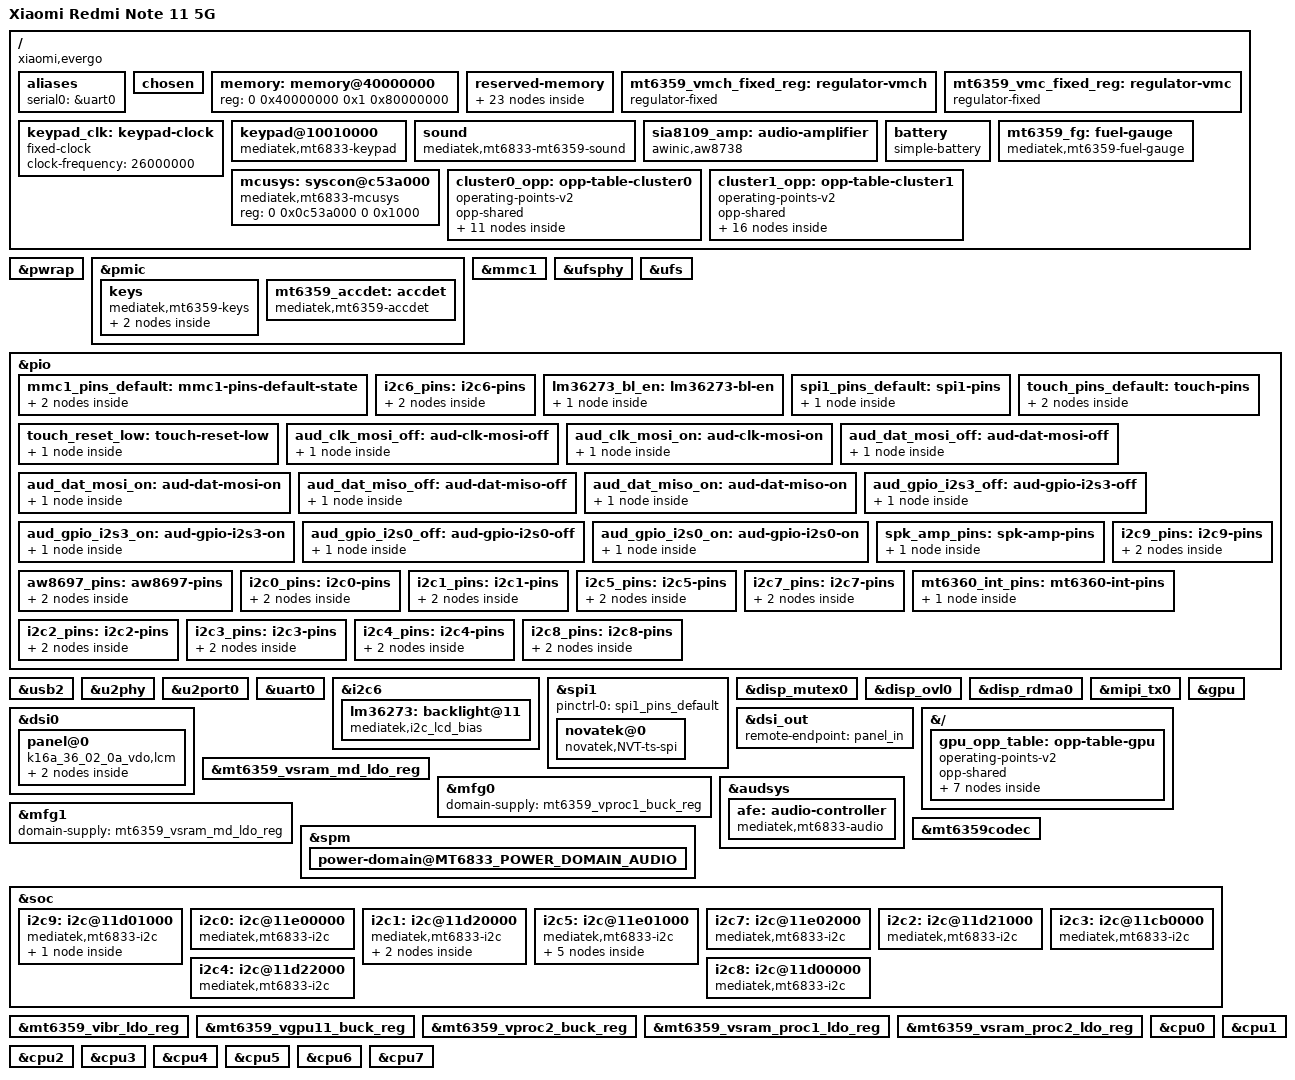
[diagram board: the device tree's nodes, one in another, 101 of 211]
// SPDX-License-Identifier: GPL-2.0
/*
 * Device Tree Source for Xiaomi Redmi Note 11 5G (evergo)
 *
 * The MT6833 SoC support (mt6833.dtsi, pinctrl and clock drivers) was
 * brought up in mainline for the Xiaomi Poco M3 Pro 5G (camellia) by
 * Ryo "evilMyQueen" Yamada <evilMyQueen@mainlining.org>; this file ports
 * that bring-up to the evergo.
 *
 * Current state: this is a bring-up tree. The UART console works, while
 * the SD card and USB still need the topckgen/infracfg clocks and the
 * pwrap/PMIC (MT6359) support that are not wired up yet.
 */

/dts-v1/;

#include <dt-bindings/clock/mediatek,mt6833-clk.h>
#include <dt-bindings/power/mediatek,mt6833-power.h>
#include <dt-bindings/gpio/gpio.h>
#include <dt-bindings/input/input.h>
#include <dt-bindings/interrupt-controller/irq.h>
#include <dt-bindings/iio/adc/mediatek,mt6359-auxadc.h>
#include <dt-bindings/leds/common.h>
#include <dt-bindings/pinctrl/mediatek,mt6833-pinfunc.h>

#include "mt6833.dtsi"
#include "mt6359.dtsi"

/ {
	chassis-type = "handset";
	compatible = "xiaomi,evergo", "mediatek,mt6833";
	model = "Xiaomi Redmi Note 11 5G";

	aliases {
		serial0 = &uart0;
	};

	chosen {
		#address-cells = <2>;
		#size-cells = <2>;
		ranges;

		/*
		 * UART0 is the only reliable observation point during
		 * bring-up, so the console is kept on it.
		 *
		 * initcall_blacklist: an early build died inside
		 * exynos4_pm_init_power_domain (an Exynos PM-domain driver that
		 * has no business probing on MT6833, but does - the DT must be
		 * matching one of its compatibles) and never returned from it.
		 * Skipping that one initcall costs nothing here and tells us
		 * whether the rest of the boot can get past 0.31s.
		 */
		/*
		 * b268: weston's KMS dumb buffers are carved out of the CMA
		 * pool; one 1080x2400x4 frame is ~10.4 MB, and after fbcon
		 * took its own buffer the 32 MB default left nothing, so the
		 * first weston surface died with
		 *   KMS: DRM_IOCTL_MODE_CREATE_DUMB failed: Out of memory
		 * 256 MB is comfortable on this 8 GiB unit.
		 */
		bootargs = "earlycon=mtk8250,0x11002000 console=evenring console=ttyS0,921600n8 console=tty0 loglevel=4 printk.devkmsg=on mem_sleep_default=s2idle clk_ignore_unused pd_ignore_unused regulator_ignore_unused panic=10 watchdog_thresh=30 initcall_blacklist=exynos4_pm_init_power_domain fbcon=nodefer cma=256M";
		stdout-path = "serial0:921600n8";
	};

	/*
	 * LK reports the DRAM it trained in /memory of the DT it hands over;
	 * this unit is an 8 GiB one. Keep this in sync with the variant in use
	 * (4/6/8 GiB evergo variants exist).
	 */
	memory: memory@40000000 {
		device_type = "memory";
		reg = <0 0x40000000 0x1 0x80000000>;
	};

	/*
	 * The regions below match exactly what the MT6833 LK of the evergo
	 * injects into the DT it hands to the kernel (its mblock-N-* entries,
	 * dumped from a running device). Do not change them lightly: a wrong
	 * TEE/ATF/GZ region makes the kernel die before the console is up.
	 * The LK also fixes up the DRAM size in /memory.
	 */
	reserved-memory {
		#address-cells = <2>;
		#size-cells = <2>;
		ranges;

		/* CONN reserved memory, same shape as the vendor DTB.  Dynamic regions,
		 * so matched by size/alignment/alloc-ranges; 16 MB alignment makes the
		 * placement stable across boots.
		 */
		consys_reserved: consys-reserve-memory {
			compatible = "mediatek,consys-reserve-memory";
			no-map;
			size = <0 0x500000>;
			alignment = <0 0x1000000>;
			alloc-ranges = <0 0x40000000 0 0x80000000>;
		};

		/* The WiFi firmware body, its HIF rings and the CONN patches all live in
		 * the one window the MCU reads; the driver also needs dma ops
		 * ("shared-dma-pool") and a 'size' property, so this node deliberately
		 * overlaps consys_reserved.
		 */
		wifi_reserved: wifi-reserve-memory {
			compatible = "shared-dma-pool";
			no-map;
			size = <0 0x600000>;
			alignment = <0 0x1000000>;
			alloc-ranges = <0 0x40000000 0 0x80000000>;
		};

		dpm_reserved: memory@ffe60000 {
			reg = <0 0xffe60000 0 0x190000>;
			no-map;
		};

		/* Framebuffer shared with the bootloader (LK) */
		framebuffer_reserved: memory@7c610000 {
			reg = <0 0x7c610000 0 0x1df0000>;
		};

		minirdump: memory@48170000 {
			reg = <0 0x48170000 0 0x10000>;
			no-map;
		};

		/*
		 * LK keeps its AEE/ramoops buffer here; this is our only way to see
		 * kernel output after a crash (read /sys/fs/pstore on the next boot).
		 */
		/*
		 * Pstore/ramoops console area. The MTK LK copies it into the expdb
		 * partition on the next boot, which is the only way to read kernel
		 * output on a board without UART. The first bytes are also used for
		 * early breadcrumbs by arch/arm64/kernel/setup.c before the ramoops
		 * driver exists.
		 *
		 * Same zones as the vendor kernel asks for on its command line
		 * (console 0x40000 then pmsg 0x10000, no record-size: that would
		 * shift both), so the layout matches what Android expects as well.
		 */
		ramoops@48090000 {
			compatible = "ramoops";
			reg = <0 0x48090000 0 0xe0000>;
			no-map;
			console-size = <0x40000>;
			pmsg-size = <0x10000>;
		};

		aee_debug_kinfo: memory@48080000 {
			reg = <0 0x48080000 0 0x10000>;
			no-map;
		};

		picachu: memory@bfd00000 {
			reg = <0 0xbfd00000 0 0x80000>;
			no-map;
		};

		mcupm_reserved: memory@7f500000 {
			reg = <0 0x7f500000 0 0x100000>;
			no-map;
		};

		tee_reserved: memory@70000000 {
			reg = <0 0x70000000 0 0x5b00000>;
			no-map;
		};

		tee_ree_reserved: memory@7e400000 {
			reg = <0 0x7e400000 0 0xc00000>;
			no-map;
		};

		tee_log_reserved: memory@bfc00000 {
			reg = <0 0xbfc00000 0 0x20000>;
			no-map;
		};

		sspm_reserved: memory@7feb0000 {
			reg = <0 0x7feb0000 0 0x100000>;
			no-map;
		};

		tee_secmem: memory@7f000000 {
			reg = <0 0x7f000000 0 0x400000>;
			no-map;
		};

		atf_log_reserved: memory@bfe00000 {
			reg = <0 0xbfe00000 0 0x40000>;
			no-map;
		};

		atf_ramdump_reserved: memory@bff80000 {
			reg = <0 0xbff80000 0 0x80000>;
			no-map;
		};

		atf_reserved: memory@48c00000 {
			reg = <0 0x48c00000 0 0x200000>;
			no-map;
		};

		log_store: memory@7ffbf000 {
			reg = <0 0x7ffbf000 0 0x40000>;
		};

		gz_log: memory@7f400000 {
			reg = <0 0x7f400000 0 0x41000>;
		};

		gz: memory@7f600000 {
			reg = <0 0x7f600000 0 0x800000>;
			no-map;
		};

		emi_mbist_buf: memory@7ffff000 {
			reg = <0 0x7ffff000 0 0x1000>;
			no-map;
		};

		/* DDR rank markers reserved by LK */
		dramc_rk0: memory@13ffff000 {
			reg = <1 0x3ffff000 0 0x1000>;
			no-map;
		};

		dramc_rk1: memory@23ffff000 {
			reg = <2 0x3ffff000 0 0x1000>;
			no-map;
		};
	};

	/*
	 * FIXME: the MT6359 is not available yet (the MT6833 pwrap is not
	 * supported by the mainline driver), so the SD card supplies are
	 * modelled as always-on fixed regulators. This only allows
	 * high-speed modes until the PMIC regulators are wired up.
	 */
	mt6359_vmch_fixed_reg: regulator-vmch {
		compatible = "regulator-fixed";
		regulator-name = "vmch";
		regulator-min-microvolt = <3300000>;
		regulator-max-microvolt = <3300000>;
		regulator-enable-ramp-delay = <60>;
		regulator-always-on;
	};

	mt6359_vmc_fixed_reg: regulator-vmc {
		compatible = "regulator-fixed";
		regulator-name = "vmc";
		regulator-min-microvolt = <3300000>;
		regulator-max-microvolt = <3300000>;
		regulator-enable-ramp-delay = <60>;
		regulator-always-on;
	};
};

/*
 * PMIC: the MT6359(P) sits behind the MT6833 PMIC wrapper and is described
 * by mt6359.dtsi. Its interrupt line is wired to GPIO118 on the evergo
 * (taken from the vendor DT); the wrapper's own interrupt is on SPI 220.
 */
&pwrap {
	status = "okay";
};

&pmic {
	interrupts-extended = <&pio 118 IRQ_TYPE_LEVEL_HIGH>;
};

/*
 * SD card slot. 4-bit bus, high-speed only for now: on this board VMMC/VQMMC
 * are the MT6360's LDO5/LDO3, which mainline has no driver for yet, so they
 * are modelled as always-on fixed regulators. That also keeps the UHS modes
 * out of reach, as they need a switchable 1.8 V VQMMC.
 */
&mmc1 {
	status = "okay";
	pinctrl-names = "default";
	pinctrl-0 = <&mmc1_pins_default>;
	bus-width = <4>;
	max-frequency = <50000000>;
	cap-sd-highspeed;
	no-sdio;
	no-mmc;
	/* FIXME: verify the card detect pin on the evergo */
	broken-cd;
	vmmc-supply = <&mt6359_vmch_fixed_reg>;
	vqmmc-supply = <&mt6359_vmc_fixed_reg>;
};

/*
 * UFS: enabled on purpose - this is step one of the bring-up, now that the
 * rest of the port is stable enough to survive a failure and tell us about it.
 *
 * Two things have changed since b73 was killed by this:
 *
 *  - LK's own log shows it brings the link up on this board already:
 *    "[UFS] ufs id: H9HQ21AFAMADAR", "RX HS-G3, setting is 3",
 *    "TX HS-G3, setting is 3", "HS-G3-2, 1 lane".  So the rails, the hardware
 *    and the vendor's timing sequence are known good.  What is new here is
 *    the mainline ufs-mediatek driver, which matches this controller only
 *    through its mt8183 fallback (the driver's table has mt8183 and mt8195 but
 *    no mt6833) and therefore runs mt8183 register paths on an mt6833.
 *  - The tick-2 SIGBUS that used to kill init is fixed, so a hang here no
 *    longer hides behind it, and the log survives far enough to name the step
 *    that broke.
 *
 * If the probe hangs, the ring frames LK flushes on the next boot will show
 * the last thing the driver did.  That is the point of this build.
 */
&ufsphy {
	status = "okay";
};

&ufs {
	status = "okay";
};

&pio {
	mmc1_pins_default: mmc1-pins-default-state {
		pins-clk {
			pinmux = <PINMUX_GPIO125__FUNC_MSDC1_CLK>;
			drive-strength = <3>;
			bias-pull-down = <MTK_PUPD_SET_R1R0_10>;
		};

		pins-cmd-dat {
			pinmux = <PINMUX_GPIO128__FUNC_MSDC1_DAT0>,
				 <PINMUX_GPIO127__FUNC_MSDC1_DAT1>,
				 <PINMUX_GPIO129__FUNC_MSDC1_DAT2>,
				 <PINMUX_GPIO130__FUNC_MSDC1_DAT3>,
				 <PINMUX_GPIO126__FUNC_MSDC1_CMD>;
			input-enable;
			drive-strength = <3>;
			bias-pull-up = <MTK_PUPD_SET_R1R0_01>;
		};
	};
};

&usb2 {
	status = "okay";
	/*
	 * otg, matching the SoC dtsi -- this line used to say "peripheral" and
	 * that silently overrode it, because this file is included after
	 * mt6833.dtsi and the later property wins.
	 *
	 * The consequence was not obvious: with dr_mode = peripheral the mediatek
	 * musb glue comes up as MUSB_PERIPHERAL, mtk_musb_init() therefore skips
	 * mtk_otg_switch_init(), and no usb_role_switch is registered at all --
	 * /sys/class/usb_role stays empty, so there is no way to drive the role
	 * (and hence the PHY's power-on path through the role callback) from
	 * userspace.
	 */
	/*
	 * full-speed, not high-speed.
	 *
	 * The glue now passes this on to musb as config->maximum_speed, which is
	 * what decides whether musb_start() enables high speed at all.  With high
	 * speed enabled the controller latched POWER.HSMODE (a leftover from the
	 * bootloader's own high-speed download mode) and musb told the gadget
	 * layer it was on a 480 Mbps link - so the gadget advertised 512-byte
	 * bulk endpoints on a link that had negotiated 12 Mbps, and Windows
	 * refused to start the device.  The high-speed attach on this board also
	 * looks marginal: BABBLE interrupts were showing up during enumeration,
	 * which is data-line trouble, and matches the descriptor exchange
	 * working one attempt and failing the next.
	 *
	 * A CDC-ACM console at 115200 baud does not need more than 12 Mbps.
	 */
	dr_mode = "otg";
	maximum-speed = "high-speed";
};

&u2phy {
	status = "okay";
};

&u2port0 {
	status = "okay";
};

&uart0 {
	status = "okay";
};

/*
 * PMIC: reverted for the bring-up bisect. The pwrap/MT6359 nodes (and the
 * real clock wiring) come back once the kernel boots again.
 */

/*
 * Display: the K16A panel is driven as 3-trio C-PHY (no clock lane), so the
 * DSI node selects C-PHY mode and hands over the panel module's own LP/HS
 * cycle counts (11/35/26) for the C-PHY blanking maths.  The bias and
 * backlight chip (LM36273) lives on i2c6.
 */
&i2c6 {
	status = "okay";
	clock-frequency = <400000>;
	pinctrl-names = "default";
	pinctrl-0 = <&i2c6_pins>;

	lm36273: backlight@11 {
		compatible = "mediatek,i2c_lcd_bias";
		reg = <0x11>;

		/*
		 * Chip + panel DVDD.  The vendor's panel driver enables this
		 * rail (1.3 V) before its first I2C access; without it the
		 * chip does not even ACK on the bus (an all-NACK sweep).
		 */
		vdd-supply = <&mt6359_vcn13_ldo_reg>;
		/*
		 * Vendor "lcm-bl-enable" pin, driven high right before the
		 * first LM36273 register access.  Done with a pinctrl state
		 * instead of a consumer gpio: gpiod lookups on this tree never
		 * resolve (probe stuck in -EPROBE_DEFER forever, log said
		 * "deferred probe pending: lm36273-backlight: enable gpio").
		 */
		pinctrl-names = "default";
		pinctrl-0 = <&lm36273_bl_en>;
	};
};

/*
 * Touchscreen: Novatek NT36672C on SPI1 (vendor wiring: CLK=GPIO27,
 * CSB=GPIO28, MO=GPIO29, MI=GPIO30, reset=GPIO13, irq=GPIO14).  The driver
 * is the mainline adaptation of the vendor NT36672C driver, expecting the
 * vendor "novatek,*" properties.
 */
&spi1 {
	status = "okay";
	pinctrl-names = "default";
	pinctrl-0 = <&spi1_pins_default>;

	novatek@0 {
		compatible = "novatek,NVT-ts-spi";
		reg = <0>;
		spi-max-frequency = <9600000>;

		/*
		 * CS timing for the NT36672C.  The vendor driver fed the
		 * controller cs_setuptime=30 / cs_holdtime=25 / cs_idletime=5
		 * ticks through its private controller_data; the mainline
		 * controller takes these standard properties instead.  Values
		 * are rounded up for the ~54.6 MHz SPI source clock
		 * (mainpll/20, ~18.3 ns/tick).
		 */
		spi-cs-setup-delay-ns = <546>;
		spi-cs-hold-delay-ns = <455>;
		spi-cs-inactive-delay-ns = <91>;

		/* irq = GPIO14.  The controller pulses INT low when a packet is
		 * ready, so a falling edge gives exactly one interrupt per packet.
		 * A level trigger storms (~8000/s), a rising edge never fires. */
		interrupt-parent = <&pio>;
		interrupts = <14 IRQ_TYPE_EDGE_FALLING>;
		irq-gpios = <&pio 14 GPIO_ACTIVE_LOW>;

		novatek,reset-gpio = <&pio 13 GPIO_ACTIVE_LOW>;
		reset-gpios = <&pio 13 GPIO_ACTIVE_LOW>;
		novatek,irq-gpio = <&pio 14 GPIO_ACTIVE_LOW>;
		novatek,swrst-n8-addr = <0x03F0FE>;
		novatek,spi-rd-fast-addr = <0x03F310>;

		pinctrl-names = "default", "reset_low";
		pinctrl-0 = <&touch_pins_default>;
		pinctrl-1 = <&touch_reset_low>;
	};
};

&pio {
	i2c6_pins: i2c6-pins {
		/*
		 * MTK i2c pads need their internal pull-up.  With bias-disable
		 * the bus never goes high, the controller waits for a free bus
		 * forever (START stays set, no interrupt ever fires) and every
		 * transfer times out.
		 */
		pins-scl {
			pinmux = <PINMUX_GPIO109__FUNC_SCL6>;
			bias-pull-up;
		};

		pins-sda {
			pinmux = <PINMUX_GPIO110__FUNC_SDA6>;
			bias-pull-up;
		};
	};

        /* vendor "lcm-bl-enable" (pin 87), for the LM36273 backlight chip */
        lm36273_bl_en: lm36273-bl-en {
                pins {
                        pinmux = <PINMUX_GPIO87__FUNC_GPIO87>;
                        output-high;
                };
        };

        /* SPI1 pads for the NT36672C touchscreen (vendor pinmux table) */
        spi1_pins_default: spi1-pins {
                pins-spi {
                        pinmux = <PINMUX_GPIO27__FUNC_SPI1_CLK>,
                                 <PINMUX_GPIO28__FUNC_SPI1_CSB>,
                                 <PINMUX_GPIO29__FUNC_SPI1_MO>,
                                 <PINMUX_GPIO30__FUNC_SPI1_MI>;
                        drive-strength = <2>;
                };
        };

        /* touch reset = GPIO13 (driven high = released), irq = GPIO14 */
        touch_pins_default: touch-pins {
                pins-rst {
                        pinmux = <PINMUX_GPIO13__FUNC_GPIO13>;
                        output-high;
                };
                pins-irq {
                        pinmux = <PINMUX_GPIO14__FUNC_GPIO14>;
                        bias-pull-up;
                };
        };

        /* reset-pulse state -- pull TP_RST (GPIO13) low */
        touch_reset_low: touch-reset-low {
                pins-rst {
                        pinmux = <PINMUX_GPIO13__FUNC_GPIO13>;
                        output-low;
                };
        };
};

&disp_mutex0 {
	status = "okay";
};

&disp_ovl0 {
	status = "okay";
};

&disp_rdma0 {
	status = "okay";
};

&mipi_tx0 {
	status = "okay";
};

&dsi0 {
	status = "okay";

	mediatek,cphy;
	mediatek,hs-prpr = <11>;
	mediatek,hs-zero = <35>;
	mediatek,hs-trail = <26>;

	/*
	 * This unit carries the CSOT module - LK reports "we will use lcm:
	 * k16a_42_02_0b_vdo".  A Tianma unit uses the same node with
	 * compatible = "k16a_36_02_0a_vdo,lcm" instead.
	 *
	 * lcd_dvdd (MT6359 VCN13) is left out on purpose: the driver treats it
	 * as optional so the panel can come up while the PMIC side is still in
	 * progress.
	 */
	panel@0 {
		compatible = "k16a_36_02_0a_vdo,lcm";
		reg = <0>;

		backlight = <&lm36273>;

		pm-enable-gpios = <&pio 136 GPIO_ACTIVE_HIGH>;
		lcm-bl-enable-gpios = <&pio 87 GPIO_ACTIVE_HIGH>;
		reset-gpios = <&pio 86 GPIO_ACTIVE_HIGH>;
		bias-gpios = <&pio 137 GPIO_ACTIVE_HIGH>,
			     <&pio 138 GPIO_ACTIVE_HIGH>;

		port {
			panel_in: endpoint {
				remote-endpoint = <&dsi_out>;
			};
		};
	};
};

&dsi_out {
	remote-endpoint = <&panel_in>;
};

&gpu {
	status = "okay";

	/*
	 * GPU DVFS: only the core rail is described here, and the OPP table
	 * below keeps it at a fixed 0.78125 V for every frequency, so devfreq
	 * changes the MFGPLL rate only and never the voltage.
	 *
	 * The GPU SRAM rail (vendor _vsram_gpu, MT6359 VSRAM_MD LDO) is *not*
	 * a device supply: it belongs to the MFG1 power domain (domain-supply
	 * below), which mtk-pm-domains enables before the MTCMOS handshake,
	 * as on the upstream mt8183b/mt8186/mt8188 MediaTek GPUs.  Listing it
	 * here as well would give panfrost two OPP regulators, and panfrost
	 * then refuses to start devfreq ("More than 1 supply is not supported
	 * yet") because the OPP core needs per-supply voltages for that.
	 */
	mali-supply = <&mt6359_vproc1_buck_reg>;
	operating-points-v2 = <&gpu_opp_table>;
};

/*
 * GPU OPP table (DVFS 390-955 MHz): the vendor voltages rely on EEMG
 * calibration, which mainline does not do.  Running them uncalibrated makes
 * panfrost fault (JOB_READ_FAULT, AS1 translation faults, job timeouts) and
 * compositors fall back to software rendering.  The a22x-mainline port of the
 * same MT6833 found a fixed 0.78125 V core rail plus 0.85 V GPU SRAM clean on
 * every boot, so use that for all OPPs: DVFS only changes the MFGPLL rate.
 *
 * 955 MHz is the ceiling: MFGPLL_CON1 ignores PCW values above the 955 MHz
 * setting on this chip (the Dimensity 700 GPU is rated for 950 MHz), so the
 * vendor 1000/1068 MHz entries are deliberately left out.
 */
&{/} {
	gpu_opp_table: opp-table-gpu {
		compatible = "operating-points-v2";
		opp-shared;

		opp-390000000 { opp-hz = /bits/ 64 <390000000>; opp-microvolt = <781250>; };
		opp-467000000 { opp-hz = /bits/ 64 <467000000>; opp-microvolt = <781250>; };
		opp-545000000 { opp-hz = /bits/ 64 <545000000>; opp-microvolt = <781250>; };
		opp-622000000 { opp-hz = /bits/ 64 <622000000>; opp-microvolt = <781250>; };
		opp-700000000 { opp-hz = /bits/ 64 <700000000>; opp-microvolt = <781250>; };
		opp-790000000 { opp-hz = /bits/ 64 <790000000>; opp-microvolt = <781250>; };
		opp-880000000 { opp-hz = /bits/ 64 <880000000>; opp-microvolt = <781250>; };
	};
};

/* GPU SRAM rail: fixed 0.85 V (see the OPP comment above). */
&mt6359_vsram_md_ldo_reg {
	regulator-min-microvolt = <850000>;
	regulator-max-microvolt = <850000>;
};

/*
 * The MTCMOS power-on sequence needs its rails up first: the scpsys
 * driver enables "domain-supply" before flipping PWR_ON/PWR_ON_2ND,
 * mirroring the vendor gpufreq order (vgpu/vsram_gpu first, then mtcmos).
 * Same layout as mt8188-geralt upstream: core rail on mfg0, SRAM rail
 * on mfg1.  Vendor names: _vgpu = VPROC1 buck, _vsram_gpu = VSRAM_MD.
 *
 * mfg1 is the only owner of the GPU SRAM rail (the gpu node no longer
 * claims it as a device supply), and only mfg0's core rail is exposed to
 * panfrost as "mali" for the OPP core to keep at 0.78125 V.
 */
&mfg0 {
	domain-supply = <&mt6359_vproc1_buck_reg>;
};

&mfg1 {
	domain-supply = <&mt6359_vsram_md_ldo_reg>;
};

/*
 * Hardware keys: the MT6359 PMIC provides KEY_POWER and (on this board) the
 * volume-down button through its "home" key; volume-up is wired to the SoC
 * keypad matrix (single key, KPCOL0/1), as on the a22x MT6833 port.
 */
&pmic {
	keys {
		compatible = "mediatek,mt6359-keys";

		power-key {
			linux,keycodes = <116>;		/* KEY_POWER */
			wakeup-source;
		};

		home-key {
			linux,keycodes = <114>;		/* KEY_VOLUMEDOWN */
		};
	};
};

/ {
	keypad_clk: keypad-clock {
		compatible = "fixed-clock";
		#clock-cells = <0>;
		clock-frequency = <26000000>;
	};

	keypad@10010000 {
		compatible = "mediatek,mt6833-keypad", "mediatek,mt6779-keypad";
		reg = <0 0x10010000 0 0x1000>;
		interrupts = <GIC_SPI 74 IRQ_TYPE_EDGE_RISING>;
		clocks = <&keypad_clk>;
		clock-names = "kpd";
		linux,keymap = <0 115>;		/* rows*cols keycodes: (0,0)=none, (0,1)=KEY_VOLUMEUP */
		keypad,num-rows = <1>;
		keypad,num-columns = <2>;
		debounce-delay-ms = <32>;
		wakeup-source;
	};
};

/*
 * ---------------------------------------------------------------------
 * Audio: MT6833 AFE (MT8192-compatible) + MT6359 codec + SIA8109 amp
 * ---------------------------------------------------------------------
 *
 * Layout taken from the vendor evergo DTS (mt6833.dts / evergo.dts):
 *  - MTKAIF link AFE <-> MT6359 on AUD_CLK_MOSI (GPIO152), AUD_SYNC_MOSI
 *    (GPIO153), AUD_DAT_MOSI0/1 (GPIO154/155), AUD_DAT_MISO0/1
 *    (GPIO159/160);
 *  - the SIA8109 speaker amplifier hangs off the MT6359 line output and
 *    is enabled/configured through its one-wire interface on GPIO131,
 *    which the mainline aw8738 driver drives (mode 6, verified on the
 *    same MT6359+SIA8109 combination on the a22x port).
 *
 * The AFE is a child of the audsys clock controller: the audsys driver
 * populates its children (of_platform_populate), exactly like MT8192.
 */
&pio {
	aud_clk_mosi_off: aud-clk-mosi-off {
		pins-off {
			pinmux = <PINMUX_GPIO152__FUNC_GPIO152>,
				 <PINMUX_GPIO153__FUNC_GPIO153>;
			input-enable;
			bias-pull-down;
		};
	};

	aud_clk_mosi_on: aud-clk-mosi-on {
		pins-on {
			pinmux = <PINMUX_GPIO152__FUNC_AUD_CLK_MOSI>,
				 <PINMUX_GPIO153__FUNC_AUD_SYNC_MOSI>;
			input-schmitt-enable;
			bias-disable;
		};
	};

	aud_dat_mosi_off: aud-dat-mosi-off {
		pins-off {
			pinmux = <PINMUX_GPIO154__FUNC_GPIO154>,
				 <PINMUX_GPIO155__FUNC_GPIO155>;
			input-enable;
			bias-pull-down;
		};
	};

	aud_dat_mosi_on: aud-dat-mosi-on {
		pins-on {
			pinmux = <PINMUX_GPIO154__FUNC_AUD_DAT_MOSI0>,
				 <PINMUX_GPIO155__FUNC_AUD_DAT_MOSI1>;
			input-schmitt-enable;
			bias-disable;
		};
	};

	aud_dat_miso_off: aud-dat-miso-off {
		pins-off {
			pinmux = <PINMUX_GPIO159__FUNC_GPIO159>,
				 <PINMUX_GPIO160__FUNC_GPIO160>;
			input-enable;
			bias-pull-down;
		};
	};

	aud_dat_miso_on: aud-dat-miso-on {
		pins-on {
			pinmux = <PINMUX_GPIO159__FUNC_AUD_DAT_MISO0>,
				 <PINMUX_GPIO160__FUNC_AUD_DAT_MISO1>;
			input-schmitt-enable;
			bias-disable;
		};
	};

	aud_gpio_i2s3_off: aud-gpio-i2s3-off {
		pins-off {
			pinmux = <PINMUX_GPIO40__FUNC_GPIO40>,
				 <PINMUX_GPIO41__FUNC_GPIO41>,
				 <PINMUX_GPIO43__FUNC_GPIO43>;
			input-enable;
			bias-pull-down;
		};
	};

	aud_gpio_i2s3_on: aud-gpio-i2s3-on {
		pins-on {
			pinmux = <PINMUX_GPIO40__FUNC_I2S3_BCK>,
				 <PINMUX_GPIO41__FUNC_I2S3_LRCK>,
				 <PINMUX_GPIO43__FUNC_I2S3_DO>;
			input-schmitt-enable;
			bias-disable;
		};
	};

	aud_gpio_i2s0_off: aud-gpio-i2s0-off {
		pins-off {
			pinmux = <PINMUX_GPIO42__FUNC_GPIO42>;
			input-enable;
			bias-pull-down;
		};
	};

	aud_gpio_i2s0_on: aud-gpio-i2s0-on {
		pins-on {
			pinmux = <PINMUX_GPIO42__FUNC_I2S0_DI>;
			input-schmitt-enable;
			bias-disable;
		};
	};

	/* SIA8109 one-wire (reset + OWI) line on GPIO131 */
	spk_amp_pins: spk-amp-pins {
		pins-owi {
			pinmux = <PINMUX_GPIO131__FUNC_GPIO131>;
			slew-rate = <1>;
			bias-disable;
		};
	};
};

&audsys {
	afe: audio-controller {
		compatible = "mediatek,mt6833-audio";
		interrupts = <GIC_SPI 202 IRQ_TYPE_LEVEL_HIGH>;
		mediatek,apmixedsys = <&apmixedsys>;
		mediatek,infracfg = <&infracfg_ao>;
		mediatek,topckgen = <&topckgen>;
		power-domains = <&spm MT6833_POWER_DOMAIN_AUDIO>;
		clocks = <&audsys CLK_AUDSYS_AFE>,
			 <&audsys CLK_AUDSYS_DAC>,
			 <&audsys CLK_AUDSYS_DAC_PREDIS>,
			 <&audsys CLK_AUDSYS_ADC>,
			 <&audsys CLK_AUDSYS_ADDA6_ADC>,
			 <&audsys CLK_AUDSYS_22M>,
			 <&audsys CLK_AUDSYS_24M>,
			 <&audsys CLK_AUDSYS_APLL_TUNER>,
			 <&audsys CLK_AUDSYS_APLL2_TUNER>,
			 <&audsys CLK_AUDSYS_TDM>,
			 <&audsys CLK_AUDSYS_TML>,
			 <&audsys CLK_AUDSYS_NLE>,
			 <&audsys CLK_AUDSYS_DAC_HIRES>,
			 <&audsys CLK_AUDSYS_ADC_HIRES>,
			 <&audsys CLK_AUDSYS_ADC_HIRES_TML>,
			 <&audsys CLK_AUDSYS_ADDA6_ADC_HIRES>,
			 <&audsys CLK_AUDSYS_3RD_DAC>,
			 <&audsys CLK_AUDSYS_3RD_DAC_PREDIS>,
			 <&audsys CLK_AUDSYS_3RD_DAC_TML>,
			 <&audsys CLK_AUDSYS_3RD_DAC_HIRES>,
			 <&infracfg_ao CLK_IFRAO_AUDIO>,
			 <&infracfg_ao CLK_IFRAO_AUDIO_26M_BCLK>,
			 <&topckgen CLK_TOP_AUDIO_SEL>,
			 <&topckgen CLK_TOP_AUD_INTBUS_SEL>,
			 <&topckgen CLK_TOP_MAINPLL_D4_D4>,
			 <&topckgen CLK_TOP_AUD_1_SEL>,
			 <&topckgen CLK_TOP_APLL1>,
			 <&topckgen CLK_TOP_AUD_2_SEL>,
			 <&topckgen CLK_TOP_APLL2>,
			 <&topckgen CLK_TOP_AUD_ENGEN1_SEL>,
			 <&topckgen CLK_TOP_APLL1_D4>,
			 <&topckgen CLK_TOP_AUD_ENGEN2_SEL>,
			 <&topckgen CLK_TOP_APLL2_D4>,
			 <&topckgen CLK_TOP_APLL_I2S0_MCK_SEL>,
			 <&topckgen CLK_TOP_APLL_I2S1_MCK_SEL>,
			 <&topckgen CLK_TOP_APLL_I2S2_MCK_SEL>,
			 <&topckgen CLK_TOP_APLL_I2S3_MCK_SEL>,
			 <&topckgen CLK_TOP_APLL_I2S4_MCK_SEL>,
			 <&topckgen CLK_TOP_APLL_I2S5_MCK_SEL>,
			 <&topckgen CLK_TOP_APLL_I2S6_MCK_SEL>,
			 <&topckgen CLK_TOP_APLL_I2S7_MCK_SEL>,
			 <&topckgen CLK_TOP_APLL_I2S8_MCK_SEL>,
			 <&topckgen CLK_TOP_APLL_I2S9_MCK_SEL>,
			 <&topckgen CLK_TOP_APLL12_CK_DIV0>,
			 <&topckgen CLK_TOP_APLL12_CK_DIV1>,
			 <&topckgen CLK_TOP_APLL12_CK_DIV2>,
			 <&topckgen CLK_TOP_APLL12_CK_DIV3>,
			 <&topckgen CLK_TOP_APLL12_CK_DIV4>,
			 <&topckgen CLK_TOP_APLL12_CK_DIVB>,
			 <&topckgen CLK_TOP_APLL12_CK_DIV5>,
			 <&topckgen CLK_TOP_APLL12_CK_DIV6>,
			 <&topckgen CLK_TOP_APLL12_CK_DIV7>,
			 <&topckgen CLK_TOP_APLL12_CK_DIV8>,
			 <&topckgen CLK_TOP_APLL12_CK_DIV9>,
			 <&topckgen CLK_TOP_AUDIO_H_SEL>,
			 <&topckgen CLK_TOP_TCK_26M_MX9>;
		clock-names = "aud_afe_clk", "aud_dac_clk",
			      "aud_dac_predis_clk", "aud_adc_clk",
			      "aud_adda6_adc_clk", "aud_apll22m_clk",
			      "aud_apll24m_clk", "aud_apll1_tuner_clk",
			      "aud_apll2_tuner_clk", "aud_tdm_clk",
			      "aud_tml_clk", "aud_nle",
			      "aud_dac_hires_clk", "aud_adc_hires_clk",
			      "aud_adc_hires_tml", "aud_adda6_adc_hires_clk",
			      "aud_3rd_dac_clk", "aud_3rd_dac_predis_clk",
			      "aud_3rd_dac_tml", "aud_3rd_dac_hires_clk",
			      "aud_infra_clk", "aud_infra_26m_clk",
			      "top_mux_audio", "top_mux_audio_int",
			      "top_mainpll_d4_d4", "top_mux_aud_1",
			      "top_apll1_ck", "top_mux_aud_2",
			      "top_apll2_ck", "top_mux_aud_eng1",
			      "top_apll1_d4", "top_mux_aud_eng2",
			      "top_apll2_d4", "top_i2s0_m_sel",
			      "top_i2s1_m_sel", "top_i2s2_m_sel",
			      "top_i2s3_m_sel", "top_i2s4_m_sel",
			      "top_i2s5_m_sel", "top_i2s6_m_sel",
			      "top_i2s7_m_sel", "top_i2s8_m_sel",
			      "top_i2s9_m_sel", "top_apll12_div0",
			      "top_apll12_div1", "top_apll12_div2",
			      "top_apll12_div3", "top_apll12_div4",
			      "top_apll12_divb", "top_apll12_div5",
			      "top_apll12_div6", "top_apll12_div7",
			      "top_apll12_div8", "top_apll12_div9",
			      "top_mux_audio_h", "top_clk26m_clk";
	};
};

/* Audio subsystem MTCMOS: needs the 26 MHz audio bus clocks while the
 * SRAM power-down acknowledgement is polled (vendor clk-mt6833-pg.c). */
&spm {
	power-domain@MT6833_POWER_DOMAIN_AUDIO {
		reg = <MT6833_POWER_DOMAIN_AUDIO>;
		clocks = <&topckgen CLK_TOP_AUD_INTBUS_SEL>,
			 <&infracfg_ao CLK_IFRAO_AUDIO_26M_BCLK>,
			 <&infracfg_ao CLK_IFRAO_AUDIO>;
		clock-names = "audio", "audio1", "audio2";
		#power-domain-cells = <0>;
	};
};

/* MT6359 codec: the evergo microphones are DC-coupled (vendor accdet uses
 * ACC-less low-cost mode 2), so run them in DCC mode like the a22x port. */
&mt6359codec {
	mediatek,dmic-mode = <0>;
	mediatek,mic-type-0 = <3>;
	mediatek,mic-type-1 = <3>;
	mediatek,mic-type-2 = <3>;
};

&pmic {
	mt6359_accdet: accdet {
		compatible = "mediatek,mt6359-accdet";
		mediatek,mic-vol = <8>;
		mediatek,plugout-debounce = <1>;
		mediatek,mic-mode = <2>;
		mediatek,pwm-deb-setting = <0x500 0x500 0x1 0x1f0
					    0x800 0x800 0x20 0x44
					    0x4 0x1 0x5 0x3 0x3 0x5 0xe>;
		mediatek,eint-use-ext-res = <0>;
		mediatek,key-mode = <0>;
		mediatek,three-key-thr = <0 80 220 400>;
		mediatek,four-key-thr = <0 58 121 192 400>;
		mediatek,tri-key-cdd-thr = <0 121 192 600>;
	};
};

/ {
	sound: sound {
		compatible = "mediatek,mt6833-mt6359-sound";
		mediatek,platform = <&afe>;
		mediatek,accdet = <&mt6359_accdet>;
		mediatek,speaker-amplifier = <&sia8109_amp>;
		pinctrl-names = "aud_clk_mosi_off", "aud_clk_mosi_on",
				"aud_dat_mosi_off", "aud_dat_mosi_on",
				"aud_dat_miso_off", "aud_dat_miso_on",
				"aud_gpio_i2s3_off", "aud_gpio_i2s3_on",
				"aud_gpio_i2s0_off", "aud_gpio_i2s0_on";
		pinctrl-0 = <&aud_clk_mosi_off>;
		pinctrl-1 = <&aud_clk_mosi_on>;
		pinctrl-2 = <&aud_dat_mosi_off>;
		pinctrl-3 = <&aud_dat_mosi_on>;
		pinctrl-4 = <&aud_dat_miso_off>;
		pinctrl-5 = <&aud_dat_miso_on>;
		pinctrl-6 = <&aud_gpio_i2s3_off>;
		pinctrl-7 = <&aud_gpio_i2s3_on>;
		pinctrl-8 = <&aud_gpio_i2s0_off>;
		pinctrl-9 = <&aud_gpio_i2s0_on>;
	};

	/*
	 * SIA8109 analog class-D speaker amplifier.  Its one-wire interface
	 * (N rising edges after a >1 ms low, then held high) matches the
	 * AW8738 pulse protocol; mode 6 is the level the vendor driver picks
	 * for sia81x9.  It is an auxiliary device of the sound card above.
	 */
	sia8109_amp: audio-amplifier {
		compatible = "awinic,aw8738";
		mode-gpios = <&pio 131 GPIO_ACTIVE_HIGH>;
		awinic,mode = <6>;
		sound-name-prefix = "Speaker Amp";
		pinctrl-names = "default";
		pinctrl-0 = <&spk_amp_pins>;
	};
};

/*
 * Haptics: AW8697 LRA driver on the (previously undescribed) i2c9 bus.
 * Bus data from the vendor mt6833.dts: registers at 0x11d01000, DMA at
 * 0x10217900, SPI 121, IMPS I2C9 gate, pads GPIO141/142.  The actuator's
 * reset/OWI line is GPIO132 and its interrupt GPIO6 (vendor evergo.dts).
 */
&pio {
	i2c9_pins: i2c9-pins {
		pins-scl {
			pinmux = <PINMUX_GPIO141__FUNC_SCL9>;
			bias-pull-up;
		};

		pins-sda {
			pinmux = <PINMUX_GPIO142__FUNC_SDA9>;
			bias-pull-up;
		};
	};

	aw8697_pins: aw8697-pins {
		pins-reset {
			pinmux = <PINMUX_GPIO132__FUNC_GPIO132>;
			bias-disable;
			output-high;
		};

		pins-irq {
			pinmux = <PINMUX_GPIO6__FUNC_GPIO6>;
			input-enable;
			bias-pull-up;
		};
	};
};

&soc {
	i2c9: i2c@11d01000 {
		compatible = "mediatek,mt6833-i2c";
		reg = <0 0x11d01000 0 0x1000>,
		      <0 0x10217900 0 0x180>;
		interrupts = <GIC_SPI 121 IRQ_TYPE_LEVEL_HIGH>;
		clocks = <&imp_iic_wrap_s CLK_IMPS_AP_CLOCK_RO_I2C9>,
			 <&infracfg_ao CLK_IFRAO_AP_DMA>;
		clock-names = "main", "dma";
		clock-div = <5>;
		pinctrl-names = "default";
		pinctrl-0 = <&i2c9_pins>;
		#address-cells = <1>;
		#size-cells = <0>;
		status = "okay";

		aw8697_haptics: haptics@5a {
			compatible = "awinic,aw8697";
			reg = <0x5a>;
			reset-gpios = <&pio 132 GPIO_ACTIVE_LOW>;
			interrupt-parent = <&pio>;
			interrupts = <6 IRQ_TYPE_EDGE_FALLING>;
			pinctrl-names = "default";
			pinctrl-0 = <&aw8697_pins>;

			/* tuneables from the vendor evergo.dts node */
			vib_f0_pre = <1700>;
			vib_f0_coeff = <260>;
			vib_cont_drv_lev = <96>;
			vib_cont_drv_lvl_ov = <96>;
			vib_cont_td = <0x009a>;
			vib_cont_zc_thr = <0x0ff1>;
			vib_cont_num_brk = <3>;
			vib_tset = <0x12>;
			vib_r_spare = <0x68>;
			vib_bst_vol_default = <0x10>;
			vib_bstdbg = <0x30 0xeb 0xd4>;
			vib_bemf_config = <0x10 0x08 0x03 0xf8>;
		};
	};
};

/*
 * Charger / PMIC: the MT6360 companion PMIC (charger + flash LED + ADC) and
 * the MT6359 fuel gauge.  The MT6360 bus is not described by the vendor DT
 * (its i2c client is created by the bootloader); the MT6833+MT6360 reference
 * wiring puts it on i2c5 @0x34, which is also what the a22x port uses.
 * The interrupt lines are GPIO10 (IRQB) and GPIO9 (PD_IRQB).
 */
&pio {
	i2c0_pins: i2c0-pins {
		pins-scl { pinmux = <PINMUX_GPIO97__FUNC_SCL0>; bias-pull-up; };
		pins-sda { pinmux = <PINMUX_GPIO98__FUNC_SDA0>; bias-pull-up; };
	};

	i2c1_pins: i2c1-pins {
		pins-scl { pinmux = <PINMUX_GPIO99__FUNC_SCL1>; bias-pull-up; };
		pins-sda { pinmux = <PINMUX_GPIO100__FUNC_SDA1>; bias-pull-up; };
	};

	i2c5_pins: i2c5-pins {
		pins-scl { pinmux = <PINMUX_GPIO107__FUNC_SCL5>; bias-pull-up; };
		pins-sda { pinmux = <PINMUX_GPIO108__FUNC_SDA5>; bias-pull-up; };
	};

	i2c7_pins: i2c7-pins {
		pins-scl { pinmux = <PINMUX_GPIO111__FUNC_SCL7>; bias-pull-up; };
		pins-sda { pinmux = <PINMUX_GPIO112__FUNC_SDA7>; bias-pull-up; };
	};

	mt6360_int_pins: mt6360-int-pins {
		pins-irq {
			pinmux = <PINMUX_GPIO10__FUNC_GPIO10>;
			input-enable;
			bias-pull-up;
		};
	};
};

&soc {
	i2c0: i2c@11e00000 {
		compatible = "mediatek,mt6833-i2c";
		reg = <0 0x11e00000 0 0x1000>, <0 0x10217080 0 0x80>;
		interrupts = <GIC_SPI 112 IRQ_TYPE_LEVEL_HIGH>;
		clocks = <&imp_iic_wrap_w CLK_IMPW_AP_CLOCK_RO_I2C0>,
			 <&infracfg_ao CLK_IFRAO_AP_DMA>;
		clock-names = "main", "dma";
		clock-div = <5>;
		pinctrl-names = "default";
		pinctrl-0 = <&i2c0_pins>;
		#address-cells = <1>;
		#size-cells = <0>;
		status = "okay";
	};

	i2c1: i2c@11d20000 {
		compatible = "mediatek,mt6833-i2c";
		reg = <0 0x11d20000 0 0x1000>, <0 0x10217100 0 0x80>;
		interrupts = <GIC_SPI 113 IRQ_TYPE_LEVEL_HIGH>;
		clocks = <&imp_iic_wrap_ws CLK_IMPWS_AP_CLOCK_RO_I2C1>,
			 <&infracfg_ao CLK_IFRAO_AP_DMA>;
		clock-names = "main", "dma";
		clock-div = <5>;
		pinctrl-names = "default";
		pinctrl-0 = <&i2c1_pins>;
		#address-cells = <1>;
		#size-cells = <0>;
		status = "okay";

		/* AK09918 3-axis magnetometer (sensor hub cluster) */
		magnetometer@c {
			compatible = "asahi-kasei,ak09918";
			reg = <0x0c>;
			mount-matrix = "1", "0", "0",
				       "0", "1", "0",
				       "0", "0", "1";
		};

		/* TSL2522 ambient light sensor */
		light-sensor@39 {
			compatible = "amstaos,tsl2522";
			reg = <0x39>;
		};
	};

	i2c5: i2c@11e01000 {
		compatible = "mediatek,mt6833-i2c";
		reg = <0 0x11e01000 0 0x1000>, <0 0x10217500 0 0x80>;
		interrupts = <GIC_SPI 117 IRQ_TYPE_LEVEL_HIGH>;
		clocks = <&imp_iic_wrap_w CLK_IMPW_AP_CLOCK_RO_I2C5>,
			 <&infracfg_ao CLK_IFRAO_AP_DMA>;
		clock-names = "main", "dma";
		clock-div = <5>;
		pinctrl-names = "default";
		pinctrl-0 = <&i2c5_pins>;
		#address-cells = <1>;
		#size-cells = <0>;
		status = "okay";

		mt6360: pmic@34 {
			compatible = "mediatek,mt6360";
			reg = <0x34>;
			interrupt-parent = <&pio>;
			interrupts = <10 IRQ_TYPE_EDGE_FALLING>;
			interrupt-names = "IRQB";
			interrupt-controller;
			#interrupt-cells = <1>;
			wakeup-source;
			pinctrl-names = "default";
			pinctrl-0 = <&mt6360_int_pins>;

			mt6360_adc: adc {
				compatible = "mediatek,mt6360-adc";
				#io-channel-cells = <1>;
			};

			mt6360_chg: charger {
				compatible = "mediatek,mt6360-chg";
				richtek,vinovp-microvolt = <6500000>;
			};

			led-controller {
				compatible = "mediatek,mt6360-led";
				#address-cells = <1>;
				#size-cells = <0>;

				led@4 {
					reg = <4>;
					function = LED_FUNCTION_FLASH;
					color = <LED_COLOR_ID_WHITE>;
					function-enumerator = <1>;
					led-max-microamp = <100000>;
					flash-max-microamp = <750000>;
					flash-max-timeout-us = <1248000>;
				};
			};
		};
	};

	i2c7: i2c@11e02000 {
		compatible = "mediatek,mt6833-i2c";
		reg = <0 0x11e02000 0 0x1000>, <0 0x10217600 0 0x180>;
		interrupts = <GIC_SPI 119 IRQ_TYPE_LEVEL_HIGH>;
		clocks = <&imp_iic_wrap_w CLK_IMPW_AP_CLOCK_RO_I2C7>,
			 <&infracfg_ao CLK_IFRAO_AP_DMA>;
		clock-names = "main", "dma";
		clock-div = <5>;
		pinctrl-names = "default";
		pinctrl-0 = <&i2c7_pins>;
		#address-cells = <1>;
		#size-cells = <0>;
		status = "okay";
	};
};

/ {
	/*
	 * S98016 cell, 4.45 V, 5000 mAh.  OCV table generated from the
	 * vendor battery profile (bat_setting/battery_S98016_CWD_4V45_5000mah.dtsi,
	 * battery0_profile_t0) with the coulomb counter following it.
	 */
	battery: battery {
		compatible = "simple-battery";
		charge-full-design-microamp-hours = <5000000>;
		voltage-min-design-microvolt = <3400000>;
		voltage-max-design-microvolt = <4450000>;
		factory-internal-resistance-micro-ohms = <120000>;
		ocv-capacity-celsius = <25>;
		ocv-capacity-table-0 =
				       <44150000 100>,
				       <43684000 96>,
				       <43242000 92>,
				       <42772000 88>,
				       <42279000 84>,
				       <41792000 80>,
				       <41322000 76>,
				       <40868000 72>,
				       <40441000 68>,
				       <40060000 64>,
				       <39671000 60>,
				       <39135000 56>,
				       <38821000 52>,
				       <38575000 47>,
				       <38363000 43>,
				       <38178000 39>,
				       <38027000 35>,
				       <37869000 31>,
				       <37582000 27>,
				       <37377000 23>,
				       <37185000 19>,
				       <36924000 15>,
				       <36792000 11>,
				       <36489000 7>,
				       <33988000 0>;
	};

	mt6359_fg: fuel-gauge {
		compatible = "mediatek,mt6359-fuel-gauge";
		mediatek,pmic = <&pmic>;
		mediatek,sense-resistor-micro-ohms = <5000>;
		io-channels = <&pmic_adc MT6359_AUXADC_VBAT>;
		io-channel-names = "voltage";
		monitored-battery = <&battery>;
	};
};

/* The AW8697 actuator is powered from the MT6359 VIBR LDO. */
/*
 * The AW8697 actuator is powered from the MT6359 VIBR LDO.  The LRA boost
 * reports UVLO at 3.0 V, so use the regulator's top setting (3.3 V) - the
 * same rail the vendor sets up (vib_vol=9) before starting the motor.
 */
&mt6359_vibr_ldo_reg {
	regulator-min-microvolt = <3300000>;
	regulator-max-microvolt = <3300000>;
	regulator-always-on;
};

/*
 * Remaining i2c controllers from the vendor mt6833.dts.  These carry the
 * sensor cluster (i2c1: magnetometer + light/proximity), the companion
 * charger IC (i2c0) and the buses that need probing for the MT6360.
 */
&pio {
	i2c2_pins: i2c2-pins {
		pins-scl { pinmux = <PINMUX_GPIO101__FUNC_SCL2>; bias-pull-up; };
		pins-sda { pinmux = <PINMUX_GPIO102__FUNC_SDA2>; bias-pull-up; };
	};
	i2c3_pins: i2c3-pins {
		pins-scl { pinmux = <PINMUX_GPIO103__FUNC_SCL3>; bias-pull-up; };
		pins-sda { pinmux = <PINMUX_GPIO104__FUNC_SDA3>; bias-pull-up; };
	};
	i2c4_pins: i2c4-pins {
		pins-scl { pinmux = <PINMUX_GPIO105__FUNC_SCL4>; bias-pull-up; };
		pins-sda { pinmux = <PINMUX_GPIO106__FUNC_SDA4>; bias-pull-up; };
	};
	i2c8_pins: i2c8-pins {
		pins-scl { pinmux = <PINMUX_GPIO113__FUNC_SCL8>; bias-pull-up; };
		pins-sda { pinmux = <PINMUX_GPIO114__FUNC_SDA8>; bias-pull-up; };
	};
};

&soc {
	i2c2: i2c@11d21000 {
		compatible = "mediatek,mt6833-i2c";
		reg = <0 0x11d21000 0 0x1000>, <0 0x10217180 0 0x180>;
		interrupts = <GIC_SPI 114 IRQ_TYPE_LEVEL_HIGH>;
		clocks = <&imp_iic_wrap_ws CLK_IMPWS_AP_CLOCK_RO_I2C2>,
			 <&infracfg_ao CLK_IFRAO_AP_DMA>;
		clock-names = "main", "dma";
		clock-div = <5>;
		pinctrl-names = "default";
		pinctrl-0 = <&i2c2_pins>;
		#address-cells = <1>;
		#size-cells = <0>;
		status = "okay";
	};

	i2c3: i2c@11cb0000 {
		compatible = "mediatek,mt6833-i2c";
		reg = <0 0x11cb0000 0 0x1000>, <0 0x10217300 0 0x80>;
		interrupts = <GIC_SPI 115 IRQ_TYPE_LEVEL_HIGH>;
		clocks = <&imp_iic_wrap_e CLK_IMPE_AP_CLOCK_RO_I2C3>,
			 <&infracfg_ao CLK_IFRAO_AP_DMA>;
		clock-names = "main", "dma";
		clock-div = <5>;
		pinctrl-names = "default";
		pinctrl-0 = <&i2c3_pins>;
		#address-cells = <1>;
		#size-cells = <0>;
		status = "okay";
	};

	i2c4: i2c@11d22000 {
		compatible = "mediatek,mt6833-i2c";
		reg = <0 0x11d22000 0 0x1000>, <0 0x10217380 0 0x180>;
		interrupts = <GIC_SPI 116 IRQ_TYPE_LEVEL_HIGH>;
		clocks = <&imp_iic_wrap_ws CLK_IMPWS_AP_CLOCK_RO_I2C4>,
			 <&infracfg_ao CLK_IFRAO_AP_DMA>;
		clock-names = "main", "dma";
		clock-div = <5>;
		pinctrl-names = "default";
		pinctrl-0 = <&i2c4_pins>;
		#address-cells = <1>;
		#size-cells = <0>;
		status = "okay";
	};

	i2c8: i2c@11d00000 {
		compatible = "mediatek,mt6833-i2c";
		reg = <0 0x11d00000 0 0x1000>, <0 0x10217780 0 0x180>;
		interrupts = <GIC_SPI 120 IRQ_TYPE_LEVEL_HIGH>;
		clocks = <&imp_iic_wrap_s CLK_IMPS_AP_CLOCK_RO_I2C8>,
			 <&infracfg_ao CLK_IFRAO_AP_DMA>;
		clock-names = "main", "dma";
		clock-div = <5>;
		pinctrl-names = "default";
		pinctrl-0 = <&i2c8_pins>;
		#address-cells = <1>;
		#size-cells = <0>;
		status = "okay";
	};
};

/*
 * ---------------------------------------------------------------------
 * CPU DVFS: mediatek-cpufreq retunes the cluster PLLs in APMIXEDSYS
 * itself (switching the mcusys CPU_PLLDIV_CFG muxes to clk26m while a
 * PLL is changed) instead of the vendor CPUHVFS/MCUPM firmware path.
 *
 * Ported from the a22x-mainline MT6833 port, which runs the same SoC:
 * the frequencies and voltages are the vendor B20G level's unadjusted
 * (pre-EEM) values. That is the conservative set for a chip whose EEM
 * calibration table mainline cannot read.
 *
 * LITTLE stops at 950 MHz / 0.725 V because the CCI (675 MHz, needs
 * 0.725 V) shares Vproc2 with it and is not scaled yet. The big cluster
 * has its own VGPU11 rail and goes up to 2.0 GHz / 0.99375 V.
 *
 * The a22x tree later qualified its own unit further (2.203 GHz at
 * 0.9 V plus CCI DVFS). That is per-device EEM-style data, so it is
 * deliberately not copied here: a 2.087/2.203 GHz pair can be appended
 * to cluster1_opp after hardware validation, keeping the CCI at
 * >= 975 MHz / 0.825 V whenever the big cluster is above 2.0 GHz.
 */
/ {
	mcusys: syscon@c53a000 {
		compatible = "mediatek,mt6833-mcusys", "syscon";
		reg = <0 0x0c53a000 0 0x1000>;
		#clock-cells = <1>;
	};

	cluster0_opp: opp-table-cluster0 {
		compatible = "operating-points-v2";
		opp-shared;

		opp-950000000 {
			opp-hz = /bits/ 64 <950000000>;
			opp-microvolt = <725000>;
		};

		opp-1032000000 {
			opp-hz = /bits/ 64 <1032000000>;
			opp-microvolt = <743750>;
		};

		opp-1115000000 {
			opp-hz = /bits/ 64 <1115000000>;
			opp-microvolt = <762500>;
		};

		opp-1280000000 {
			opp-hz = /bits/ 64 <1280000000>;
			opp-microvolt = <800000>;
		};

		opp-1390000000 {
			opp-hz = /bits/ 64 <1390000000>;
			opp-microvolt = <825000>;
		};

		opp-1500000000 {
			opp-hz = /bits/ 64 <1500000000>;
			opp-microvolt = <850000>;
		};

		opp-1645000000 {
			opp-hz = /bits/ 64 <1645000000>;
			opp-microvolt = <893750>;
		};

		opp-1750000000 {
			opp-hz = /bits/ 64 <1750000000>;
			opp-microvolt = <925000>;
		};

		opp-1812000000 {
			opp-hz = /bits/ 64 <1812000000>;
			opp-microvolt = <943750>;
		};

		opp-1916000000 {
			opp-hz = /bits/ 64 <1916000000>;
			opp-microvolt = <975000>;
		};

		opp-2000000000 {
			opp-hz = /bits/ 64 <2000000000>;
			opp-microvolt = <1000000>;
		};
	};

	cluster1_opp: opp-table-cluster1 {
		compatible = "operating-points-v2";
		opp-shared;

		opp-725000000 {
			opp-hz = /bits/ 64 <725000000>;
			opp-microvolt = <650000>;
		};

		opp-840000000 {
			opp-hz = /bits/ 64 <840000000>;
			opp-microvolt = <681250>;
		};

		opp-898000000 {
			opp-hz = /bits/ 64 <898000000>;
			opp-microvolt = <700000>;
		};

		opp-985000000 {
			opp-hz = /bits/ 64 <985000000>;
			opp-microvolt = <725000>;
		};

		opp-1042000000 {
			opp-hz = /bits/ 64 <1042000000>;
			opp-microvolt = <737500>;
		};

		opp-1129000000 {
			opp-hz = /bits/ 64 <1129000000>;
			opp-microvolt = <756250>;
		};

		opp-1274000000 {
			opp-hz = /bits/ 64 <1274000000>;
			opp-microvolt = <800000>;
		};

		opp-1418000000 {
			opp-hz = /bits/ 64 <1418000000>;
			opp-microvolt = <843750>;
		};

		opp-1534000000 {
			opp-hz = /bits/ 64 <1534000000>;
			opp-microvolt = <875000>;
		};

		opp-1650000000 {
			opp-hz = /bits/ 64 <1650000000>;
			opp-microvolt = <906250>;
		};

		opp-1720000000 {
			opp-hz = /bits/ 64 <1720000000>;
			opp-microvolt = <925000>;
		};

		opp-1790000000 {
			opp-hz = /bits/ 64 <1790000000>;
			opp-microvolt = <943750>;
		};

		opp-1836000000 {
			opp-hz = /bits/ 64 <1836000000>;
			opp-microvolt = <950000>;
		};

		opp-1906000000 {
			opp-hz = /bits/ 64 <1906000000>;
			opp-microvolt = <968750>;
		};

		opp-1953000000 {
			opp-hz = /bits/ 64 <1953000000>;
			opp-microvolt = <981250>;
		};

		opp-2000000000 {
			opp-hz = /bits/ 64 <2000000000>;
			opp-microvolt = <993750>;
		};
	};
};

/*
 * CPU rails (vendor mapping on MT6833): big cluster = VGPU11 + VSRAM_PROC1,
 * LITTLE + CCI = VPROC2 + VSRAM_PROC2. Cap them at the vendor Vproc/Vsram
 * ceiling (1.0 V) and keep them enabled; nothing changes until cpufreq asks
 * for an OPP, and they are never switched off behind the CPU's back.
 */
&mt6359_vgpu11_buck_reg {
	regulator-min-microvolt = <600000>;
	regulator-max-microvolt = <1000000>;
	regulator-always-on;
};

&mt6359_vproc2_buck_reg {
	regulator-min-microvolt = <600000>;
	regulator-max-microvolt = <1000000>;
	regulator-always-on;
};

&mt6359_vsram_proc1_ldo_reg {
	regulator-min-microvolt = <750000>;
	regulator-max-microvolt = <1000000>;
	regulator-always-on;
};

&mt6359_vsram_proc2_ldo_reg {
	regulator-min-microvolt = <750000>;
	regulator-max-microvolt = <1000000>;
	regulator-always-on;
};

/*
 * Cortex-A55 is about 383/1024 of a Cortex-A76 per MHz; without this the
 * scheduler treats all eight CPUs as equally capable.
 */
&cpu0 {
	capacity-dmips-mhz = <383>;
	clocks = <&mcusys CLK_MCU_ARMPLL_LL_SEL>, <&clk26m>;
	clock-names = "cpu", "intermediate";
	operating-points-v2 = <&cluster0_opp>;
	proc-supply = <&mt6359_vproc2_buck_reg>;
	sram-supply = <&mt6359_vsram_proc2_ldo_reg>;
};

&cpu1 {
	capacity-dmips-mhz = <383>;
	clocks = <&mcusys CLK_MCU_ARMPLL_LL_SEL>, <&clk26m>;
	clock-names = "cpu", "intermediate";
	operating-points-v2 = <&cluster0_opp>;
	proc-supply = <&mt6359_vproc2_buck_reg>;
	sram-supply = <&mt6359_vsram_proc2_ldo_reg>;
};

&cpu2 {
	capacity-dmips-mhz = <383>;
	clocks = <&mcusys CLK_MCU_ARMPLL_LL_SEL>, <&clk26m>;
	clock-names = "cpu", "intermediate";
	operating-points-v2 = <&cluster0_opp>;
	proc-supply = <&mt6359_vproc2_buck_reg>;
	sram-supply = <&mt6359_vsram_proc2_ldo_reg>;
};

&cpu3 {
	capacity-dmips-mhz = <383>;
	clocks = <&mcusys CLK_MCU_ARMPLL_LL_SEL>, <&clk26m>;
	clock-names = "cpu", "intermediate";
	operating-points-v2 = <&cluster0_opp>;
	proc-supply = <&mt6359_vproc2_buck_reg>;
	sram-supply = <&mt6359_vsram_proc2_ldo_reg>;
};

&cpu4 {
	capacity-dmips-mhz = <383>;
	clocks = <&mcusys CLK_MCU_ARMPLL_LL_SEL>, <&clk26m>;
	clock-names = "cpu", "intermediate";
	operating-points-v2 = <&cluster0_opp>;
	proc-supply = <&mt6359_vproc2_buck_reg>;
	sram-supply = <&mt6359_vsram_proc2_ldo_reg>;
};

&cpu5 {
	capacity-dmips-mhz = <383>;
	clocks = <&mcusys CLK_MCU_ARMPLL_LL_SEL>, <&clk26m>;
	clock-names = "cpu", "intermediate";
	operating-points-v2 = <&cluster0_opp>;
	proc-supply = <&mt6359_vproc2_buck_reg>;
	sram-supply = <&mt6359_vsram_proc2_ldo_reg>;
};

&cpu6 {
	capacity-dmips-mhz = <1024>;
	clocks = <&mcusys CLK_MCU_ARMPLL_BL_SEL>, <&clk26m>;
	clock-names = "cpu", "intermediate";
	operating-points-v2 = <&cluster1_opp>;
	proc-supply = <&mt6359_vgpu11_buck_reg>;
	sram-supply = <&mt6359_vsram_proc1_ldo_reg>;
};

&cpu7 {
	capacity-dmips-mhz = <1024>;
	clocks = <&mcusys CLK_MCU_ARMPLL_BL_SEL>, <&clk26m>;
	clock-names = "cpu", "intermediate";
	operating-points-v2 = <&cluster1_opp>;
	proc-supply = <&mt6359_vgpu11_buck_reg>;
	sram-supply = <&mt6359_vsram_proc1_ldo_reg>;
};
